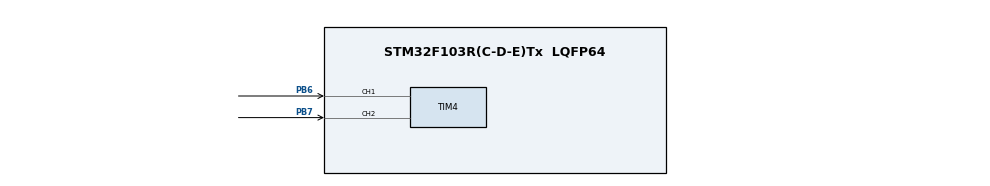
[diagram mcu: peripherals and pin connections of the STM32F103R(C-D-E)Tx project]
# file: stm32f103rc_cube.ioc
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Mcu.Family=STM32F1
Mcu.Name=STM32F103R(C-D-E)Tx
Mcu.Package=LQFP64
NVIC.PriorityGroup=NVIC_PRIORITYGROUP_4
NVIC.TIM4_IRQn=true\:0\:0\:false\:false\:true\:true\:true\:true
PA13.Mode=Serial_Wire
PA13.Signal=SYS_JTMS-SWDIO
PA14.Mode=Serial_Wire
PA14.Signal=SYS_JTCK-SWCLK
PB6.Signal=S_TIM4_CH1
PB7.Signal=S_TIM4_CH2
PC14-OSC32_IN.Mode=LSE-External-Oscillator
PC14-OSC32_IN.Signal=RCC_OSC32_IN
PC15-OSC32_OUT.Mode=LSE-External-Oscillator
PC15-OSC32_OUT.Signal=RCC_OSC32_OUT
PD0-OSC_IN.Mode=HSE-External-Oscillator
PD0-OSC_IN.Signal=RCC_OSC_IN
PD1-OSC_OUT.Mode=HSE-External-Oscillator
PD1-OSC_OUT.Signal=RCC_OSC_OUT
ProjectManager.HeapSize=0x200
ProjectManager.StackSize=0x400
ProjectManager.TargetToolchain=STM32CubeIDE
RCC.ADCPresc=RCC_ADCPCLK2_DIV6
RCC.AHBFreq_Value=72000000
RCC.APB1CLKDivider=RCC_HCLK_DIV2
RCC.APB1Freq_Value=36000000
RCC.APB1TimFreq_Value=72000000
RCC.APB2Freq_Value=72000000
RCC.APB2TimFreq_Value=72000000
RCC.HCLKFreq_Value=72000000
RCC.PLLMUL=RCC_PLL_MUL9
RCC.PLLSourceVirtual=RCC_PLLSOURCE_HSE
RCC.RTCClockSelection=RCC_RTCCLKSOURCE_LSE
RCC.SYSCLKFreq_VALUE=72000000
RCC.SYSCLKSource=RCC_SYSCLKSOURCE_PLLCLK
RCC.USBFreq_Value=48000000
RCC.USBPrescaler=RCC_USBCLKSOURCE_PLL_DIV1_5
SH.S_TIM4_CH1.0=TIM4_CH1,Encoder_Interface
SH.S_TIM4_CH2.0=TIM4_CH2,Encoder_Interface
TIM4.EncoderMode=TIM_ENCODERMODE_TI12
VP_RTC_VS_RTC_Activate.Mode=RTC_Enabled
board=custom

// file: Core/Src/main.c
/* USER CODE BEGIN Header */
/**
  ******************************************************************************
  * @file           : main.c
  * @brief          : Main program body
  ******************************************************************************
  * @attention
  *
  * Copyright (c) 2023 STMicroelectronics.
  * All rights reserved.
  *
  * This software is licensed under terms that can be found in the LICENSE file
  * in the root directory of this software component.
  * If no LICENSE file comes with this software, it is provided AS-IS.
  *
  ******************************************************************************
  */
/* USER CODE END Header */
#include "main.h"

RTC_HandleTypeDef hrtc;

TIM_HandleTypeDef htim4;

void SystemClock_Config(void);
static void MX_GPIO_Init(void);
static void MX_RTC_Init(void);
static void MX_TIM4_Init(void);

int main(void)
{

  /* MCU Configuration--------------------------------------------------------*/

  /* Reset of all peripherals, Initializes the Flash interface and the Systick. */
  HAL_Init();

  /* Configure the system clock */
  SystemClock_Config();

  /* Initialize all configured peripherals */
  MX_GPIO_Init();
  MX_RTC_Init();
  MX_TIM4_Init();

  /* Infinite loop */
  while (1)
  {

  }
}

void SystemClock_Config(void)
{
  LL_FLASH_SetLatency(LL_FLASH_LATENCY_2);
  while(LL_FLASH_GetLatency()!= LL_FLASH_LATENCY_2)
  {
  }
  LL_RCC_HSE_Enable();

   /* Wait till HSE is ready */
  while(LL_RCC_HSE_IsReady() != 1)
  {

  }
  LL_PWR_EnableBkUpAccess();
  if(LL_RCC_GetRTCClockSource() != LL_RCC_RTC_CLKSOURCE_LSE)
  {
    LL_RCC_ForceBackupDomainReset();
    LL_RCC_ReleaseBackupDomainReset();
  }
  LL_RCC_LSE_Enable();

   /* Wait till LSE is ready */
  while(LL_RCC_LSE_IsReady() != 1)
  {

  }
  if(LL_RCC_GetRTCClockSource() != LL_RCC_RTC_CLKSOURCE_LSE)
  {
    LL_RCC_SetRTCClockSource(LL_RCC_RTC_CLKSOURCE_LSE);
  }
  LL_RCC_EnableRTC();
  LL_RCC_PLL_ConfigDomain_SYS(LL_RCC_PLLSOURCE_HSE_DIV_1, LL_RCC_PLL_MUL_9);
  LL_RCC_PLL_Enable();

   /* Wait till PLL is ready */
  while(LL_RCC_PLL_IsReady() != 1)
  {

  }
  LL_RCC_SetAHBPrescaler(LL_RCC_SYSCLK_DIV_1);
  LL_RCC_SetAPB1Prescaler(LL_RCC_APB1_DIV_2);
  LL_RCC_SetAPB2Prescaler(LL_RCC_APB2_DIV_1);
  LL_RCC_SetSysClkSource(LL_RCC_SYS_CLKSOURCE_PLL);

   /* Wait till System clock is ready */
  while(LL_RCC_GetSysClkSource() != LL_RCC_SYS_CLKSOURCE_STATUS_PLL)
  {

  }
  LL_SetSystemCoreClock(72000000);

   /* Update the time base */
  if (HAL_InitTick (TICK_INT_PRIORITY) != HAL_OK)
  {
    Error_Handler();
  }
}

static void MX_RTC_Init(void)
{

  /** Initialize RTC Only
  */
  hrtc.Instance = RTC;
  hrtc.Init.AsynchPrediv = RTC_AUTO_1_SECOND;
  hrtc.Init.OutPut = RTC_OUTPUTSOURCE_ALARM;
  if (HAL_RTC_Init(&hrtc) != HAL_OK)
  {
    Error_Handler();
  }

}

static void MX_TIM4_Init(void)
{

  TIM_Encoder_InitTypeDef sConfig = {0};
  TIM_MasterConfigTypeDef sMasterConfig = {0};

  htim4.Instance = TIM4;
  htim4.Init.Prescaler = 0;
  htim4.Init.CounterMode = TIM_COUNTERMODE_UP;
  htim4.Init.Period = 65535;
  htim4.Init.ClockDivision = TIM_CLOCKDIVISION_DIV1;
  htim4.Init.AutoReloadPreload = TIM_AUTORELOAD_PRELOAD_DISABLE;
  sConfig.EncoderMode = TIM_ENCODERMODE_TI12;
  sConfig.IC1Polarity = TIM_ICPOLARITY_RISING;
  sConfig.IC1Selection = TIM_ICSELECTION_DIRECTTI;
  sConfig.IC1Prescaler = TIM_ICPSC_DIV1;
  sConfig.IC1Filter = 0;
  sConfig.IC2Polarity = TIM_ICPOLARITY_RISING;
  sConfig.IC2Selection = TIM_ICSELECTION_DIRECTTI;
  sConfig.IC2Prescaler = TIM_ICPSC_DIV1;
  sConfig.IC2Filter = 0;
  if (HAL_TIM_Encoder_Init(&htim4, &sConfig) != HAL_OK)
  {
    Error_Handler();
  }
  sMasterConfig.MasterOutputTrigger = TIM_TRGO_RESET;
  sMasterConfig.MasterSlaveMode = TIM_MASTERSLAVEMODE_DISABLE;
  if (HAL_TIMEx_MasterConfigSynchronization(&htim4, &sMasterConfig) != HAL_OK)
  {
    Error_Handler();
  }
  /* USER CODE BEGIN TIM4_Init 2 */
  HAL_TIM_Encoder_Start(&htim4, TIM_CHANNEL_ALL);
  HAL_TIM_Base_Start_IT(&htim4);
  /* USER CODE END TIM4_Init 2 */

}

static void MX_GPIO_Init(void)
{

  /* GPIO Ports Clock Enable */
  __HAL_RCC_GPIOC_CLK_ENABLE();
  __HAL_RCC_GPIOD_CLK_ENABLE();
  __HAL_RCC_GPIOA_CLK_ENABLE();
  __HAL_RCC_GPIOB_CLK_ENABLE();

}

void Error_Handler(void)
{
  __disable_irq();
  while (1)
  {
  }
}
